# ES32F0xx register map
File version: 1.0
Registers are 32-bit, read-write, reset 0x0 unless marked. A register's access mark holds for its fields unless they carry their own. Offsets are from the block's base; lines under a group give offsets from that group; [hi:lo] are bit positions; {n}, {i} and the like mark numbered series; 'fields as' and 'values as' point back to an identical list; <NAME> marks a mode.

## Memory map
0x40000000 AD16C4T0 size 0x2000 — Timer 0
0x40000400 BS16T0 size 0x2000
0x40000800 GP16C2T0 size 0x2000
0x40000C00 GP16C2T1 size 0x2000
0x40001000 BS16T1 size 0x2000
0x40001400 BS16T2 size 0x2000
0x40001800 GP16C4T0 size 0x2000
0x40001C00 BS16T3 size 0x2000
0x40004000 UART0 size 0x100 — Universal Asynchronous
0x40004400 UART1 size 0x100
0x40004800 UART2 size 0x100
0x40004C00 UART3 size 0x100
0x40005000 USART0 size 0x2000 — Universal Synchronous
0x40005400 USART1 size 0x2000
0x40006000 SPI0 size 0x2000 — Serial Peripheral Interface
0x40006400 SPI1 size 0x2000
0x40006800 SPI2 size 0x2000
0x40008000 I2C0 size 0x2000 — I2C Interface
0x40008400 I2C1 size 0x2000
0x4000B000 CAN size 0x2000 — CAN Bus
0x4000C000 DMA size 0x2000 — Direct Memory Access
0x40042000 ADC0 size 0x2000 — Analog-to-digital converter
0x40042400 ADC1 size 0x2000
0x40043000 ACMP0 size 0x2000
0x40043400 ACMP1 size 0x2000
0x40046000 WWDT size 0x200 — Watch Dog Timer
0x40046400 IWDT size 0x2000 — Watch Dog Timer
0x40048000 BKPC size 0x2000 — Backup Manage Uint
0x40048400 RTC size 0x2000 — Real Time Clock
0x40048800 TSENSE size 0x2000 — TSENSE Manage Uint
0x4004A000 DBGCON size 0x2000 — Debug Control Uint
0x40080000 SYSCFG size 0x2000 — System Configure
0x40080400 CMU size 0x2000 — Clock Manage Unit
0x40080800 RMU size 0x2000 — Reset Manage Unit
0x40080C00 PMU size 0x2000 — Pow Manage Unit
0x40081000 MSC size 0x2000 — MSC Unit
0x40084000 GPIOA size 0x2000 — General purpose I/O
0x40084040 GPIOB size 0x2000
0x40084080 GPIOC size 0x2000
0x400840C0 GPIOD size 0x2000
0x40084100 GPIOE size 0x2000
0x40084140 GPIOF size 0x2000
0x40084180 GPIOG size 0x2000
0x400841C0 GPIOH size 0x2000
0x40084300 EXTI size 0x2000 — External Interrupt
0x40085000 CRC size 0x2000 — Calculate CRC
0x40085400 CALC size 0x2000 — Calculate
0x40085800 CRYPT size 0x2000
0x40085C00 TRNG size 0x2000
0x40086000 PIS size 0x2000 — Peripheral Connect

## CMU — Clock Manage Unit
Base 0x40080400
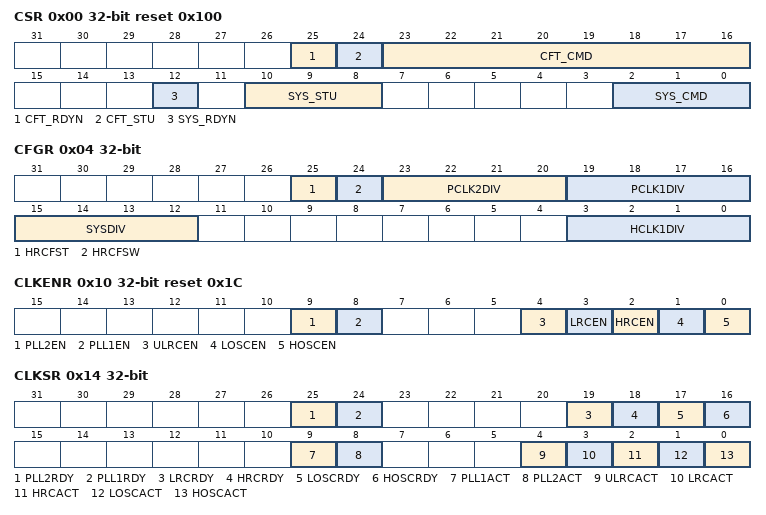
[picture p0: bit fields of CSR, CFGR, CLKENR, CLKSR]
0x00 CSR reset 0x100
  [25] CFT_RDYN, [24] CFT_STU, [23:16] CFT_CMD, [12] SYS_RDYN, [10:8] SYS_STU, [2:0] SYS_CMD
0x04 CFGR
  [25] HRCFST, [24] HRCFSW, [23:20] PCLK2DIV, [19:16] PCLK1DIV, [15:12] SYSDIV, [3:0] HCLK1DIV
0x10 CLKENR reset 0x1C
  [9] PLL2EN, [8] PLL1EN, [4] ULRCEN, [3] LRCEN, [2] HRCEN, [1] LOSCEN, [0] HOSCEN
0x14 CLKSR ro
  [25] PLL2RDY, [24] PLL1RDY, [19] LRCRDY, [18] HRCRDY, [17] LOSCRDY, [16] HOSCRDY, [9] PLL1ACT, [8] PLL2ACT, [4] ULRCACT, [3] LRCACT, [2] HRCACT, [1] LOSCACT, [0] HOSCACT
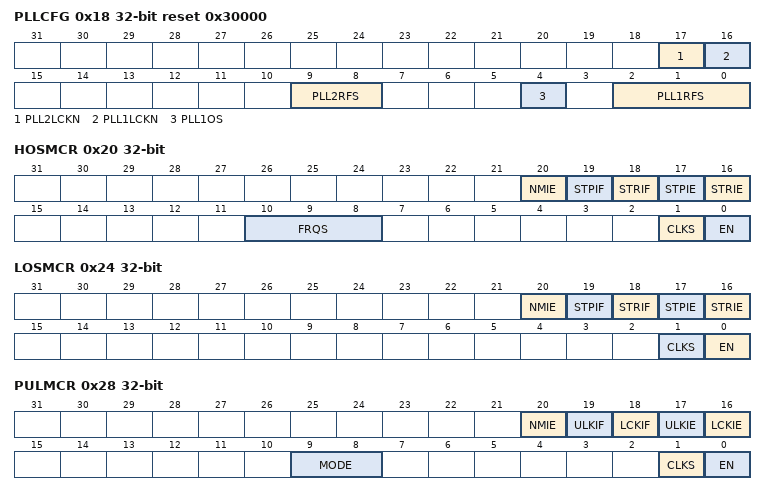
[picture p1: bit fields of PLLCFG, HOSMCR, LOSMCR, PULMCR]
0x18 PLLCFG reset 0x30000
  [17] PLL2LCKN, [16] PLL1LCKN, [9:8] PLL2RFS, [4] PLL1OS, [2:0] PLL1RFS
0x1C HOSCCFG reset 0x17
  [4:0] FREQ
0x20 HOSMCR
  [20] NMIE, [19] STPIF, [18] STRIF, [17] STPIE, [16] STRIE, [10:8] FRQS, [1] CLKS, [0] EN
0x24 LOSMCR read
  [20] NMIE, [19] STPIF, [18] STRIF, [17] STPIE, [16] STRIE, [1] CLKS, [0] EN
0x28 PULMCR
  [20] NMIE, [19] ULKIF, [18] LCKIF, [17] ULKIE, [16] LCKIE, [9:8] MODE, [1] CLKS, [0] EN
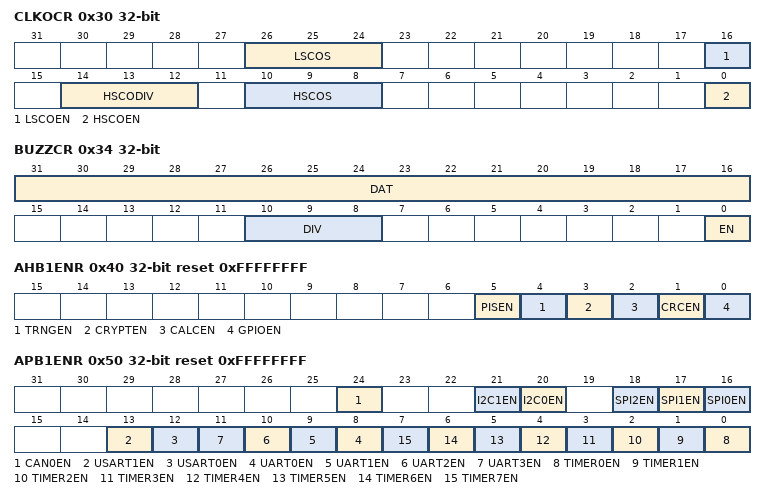
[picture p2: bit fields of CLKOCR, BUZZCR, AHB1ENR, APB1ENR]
0x30 CLKOCR
  [26:24] LSCOS, [16] LSCOEN, [14:12] HSCODIV, [10:8] HSCOS, [0] HSCOEN
0x34 BUZZCR
  [31:16] DAT, [10:8] DIV, [0] EN
0x40 AHB1ENR reset 0xFFFFFFFF
  [5] PISEN, [4] TRNGEN, [3] CRYPTEN, [2] CALCEN, [1] CRCEN, [0] GPIOEN
0x50 APB1ENR reset 0xFFFFFFFF
  [24] CAN0EN, [21] I2C1EN, [20] I2C0EN, [18] SPI2EN, [17] SPI1EN, [16] SPI0EN, [13] USART1EN, [12] USART0EN, [n+8] UART{n}EN (n=0..3), [n] TIMER{n}EN (n=0..7)
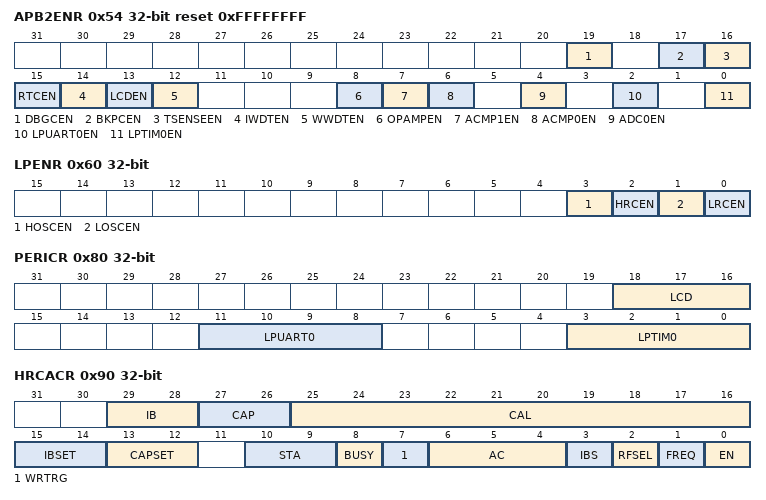
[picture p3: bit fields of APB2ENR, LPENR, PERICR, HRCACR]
0x54 APB2ENR reset 0xFFFFFFFF
  [19] DBGCEN, [17] BKPCEN, [16] TSENSEEN, [15] RTCEN, [14] IWDTEN, [13] LCDEN, [12] WWDTEN, [8] OPAMPEN, [7] ACMP1EN, [6] ACMP0EN, [4] ADC0EN, [2] LPUART0EN, [0] LPTIM0EN
0x60 LPENR
  [3] HOSCEN, [2] HRCEN, [1] LOSCEN, [0] LRCEN
0x80 PERICR
  [18:16] LCD, [11:8] LPUART0, [3:0] LPTIM0
0x90 HRCACR
  [29:28] IB, [27:26] CAP, [25:16] CAL, [15:14] IBSET, [13:12] CAPSET, [10:9] STA, [8] BUSY, [7] WRTRG, [6:4] AC, [3] IBS, [2] RFSEL, [1] FREQ, [0] EN
